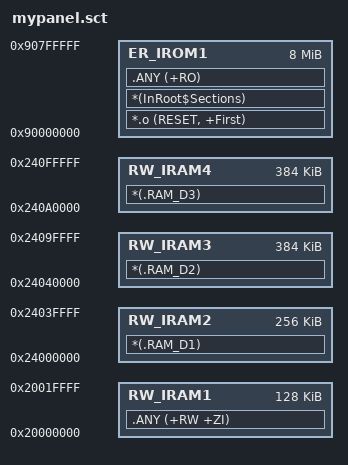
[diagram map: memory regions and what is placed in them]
LR_IROM1 0x90000000 0x00800000  {    ; load region size_region
  ER_IROM1 0x90000000 0x00800000  {  ; load address = execution address
   *.o (RESET, +First)
   *(InRoot$Sections)
   .ANY (+RO)
  }

  ; RW data - 128KB DTCM
  RW_IRAM1 0x20000000 0x00020000  {  
   .ANY (+RW +ZI)
  }

  ; RW data - 256KB AXI SRAM1(0x24000000)
  RW_IRAM2 0x24000000 0x00040000  {  
   *(.RAM_D1)
  }

  ; RW data - 384KB AXI SRAM2(0x24040000)
  RW_IRAM3 0x24040000 0x00060000  {  
   *(.RAM_D2)
  }

  ; RW data - 384KB AXI SRAM3(0x240A0000)
  RW_IRAM4 0x240A0000 0x00060000  {  
   *(.RAM_D3)
  }
}

